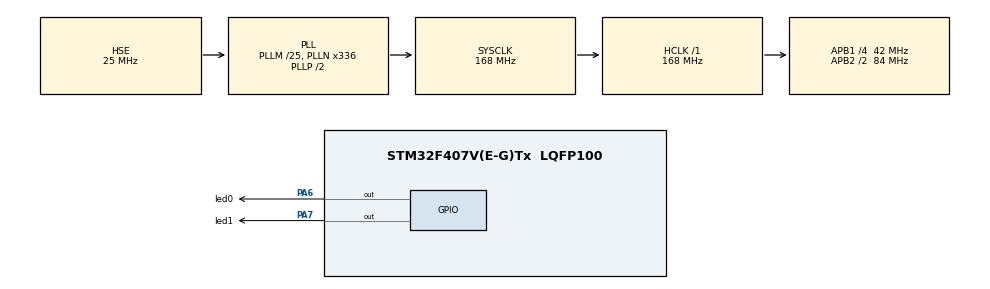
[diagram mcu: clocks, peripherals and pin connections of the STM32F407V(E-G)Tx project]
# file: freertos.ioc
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FREERTOS.Tasks01=task_led0,24,128,task_led0_start,Default,NULL,Dynamic,NULL,NULL;task_led1,24,128,task_led1_start,Default,NULL,Dynamic,NULL,NULL
Mcu.Family=STM32F4
Mcu.Name=STM32F407V(E-G)Tx
Mcu.Package=LQFP100
NVIC.PriorityGroup=NVIC_PRIORITYGROUP_4
PA13.Mode=Serial_Wire
PA13.Signal=SYS_JTMS-SWDIO
PA14.Mode=Serial_Wire
PA14.Signal=SYS_JTCK-SWCLK
PA6.GPIO_Label=led0
PA6.Signal=GPIO_Output
PA7.GPIO_Label=led1
PA7.Signal=GPIO_Output
PC14-OSC32_IN.Mode=LSE-External-Oscillator
PC14-OSC32_IN.Signal=RCC_OSC32_IN
PC15-OSC32_OUT.Mode=LSE-External-Oscillator
PC15-OSC32_OUT.Signal=RCC_OSC32_OUT
PH0-OSC_IN.Mode=HSE-External-Oscillator
PH0-OSC_IN.Signal=RCC_OSC_IN
PH1-OSC_OUT.Mode=HSE-External-Oscillator
PH1-OSC_OUT.Signal=RCC_OSC_OUT
ProjectManager.HeapSize=0x200
ProjectManager.StackSize=0x400
ProjectManager.TargetToolchain=STM32CubeIDE
RCC.48MHZClocksFreq_Value=84000000
RCC.AHBFreq_Value=168000000
RCC.APB1CLKDivider=RCC_HCLK_DIV4
RCC.APB1Freq_Value=42000000
RCC.APB1TimFreq_Value=84000000
RCC.APB2CLKDivider=RCC_HCLK_DIV2
RCC.APB2Freq_Value=84000000
RCC.APB2TimFreq_Value=168000000
RCC.CortexFreq_Value=168000000
RCC.HCLKFreq_Value=168000000
RCC.HSE_VALUE=25000000
RCC.HSI_VALUE=16000000
RCC.PLLM=25
RCC.PLLN=336
RCC.PLLSourceVirtual=RCC_PLLSOURCE_HSE
RCC.SYSCLKFreq_VALUE=168000000
RCC.SYSCLKSource=RCC_SYSCLKSOURCE_PLLCLK
RCC.VCOOutputFreq_Value=336000000
VP_FREERTOS_VS_CMSIS_V2.Mode=CMSIS_V2
board=custom

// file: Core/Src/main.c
/* USER CODE BEGIN Header */
/**
  ******************************************************************************
  * @file           : main.c
  * @brief          : Main program body
  ******************************************************************************
  * @attention
  *
  * <h2><center>&copy; Copyright (c) 2021 STMicroelectronics.
  * All rights reserved.</center></h2>
  *
  * This software component is licensed by ST under BSD 3-Clause license,
  * the "License"; You may not use this file except in compliance with the
  * License. You may obtain a copy of the License at:
  *                        opensource.org/licenses/BSD-3-Clause
  *
  ******************************************************************************
  */
/* USER CODE END Header */
#include "main.h"
#include "cmsis_os.h"
#include "gpio.h"

void SystemClock_Config(void);
void MX_FREERTOS_Init(void);

int main(void)
{

  /* MCU Configuration--------------------------------------------------------*/

  /* Reset of all peripherals, Initializes the Flash interface and the Systick. */
  HAL_Init();

  /* Configure the system clock */
  SystemClock_Config();

  /* Initialize all configured peripherals */
  MX_GPIO_Init();

  /* Init scheduler */
  osKernelInitialize();  /* Call init function for freertos objects (in freertos.c) */
  MX_FREERTOS_Init();
  /* Start scheduler */
  osKernelStart();

  /* We should never get here as control is now taken by the scheduler */
  /* Infinite loop */
  while (1)
  {

  }
}

void SystemClock_Config(void)
{
  RCC_OscInitTypeDef RCC_OscInitStruct = {0};
  RCC_ClkInitTypeDef RCC_ClkInitStruct = {0};

  /** Configure the main internal regulator output voltage
  */
  __HAL_RCC_PWR_CLK_ENABLE();
  __HAL_PWR_VOLTAGESCALING_CONFIG(PWR_REGULATOR_VOLTAGE_SCALE1);
  /** Initializes the RCC Oscillators according to the specified parameters
  * in the RCC_OscInitTypeDef structure.
  */
  RCC_OscInitStruct.OscillatorType = RCC_OSCILLATORTYPE_HSE;
  RCC_OscInitStruct.HSEState = RCC_HSE_ON;
  RCC_OscInitStruct.PLL.PLLState = RCC_PLL_ON;
  RCC_OscInitStruct.PLL.PLLSource = RCC_PLLSOURCE_HSE;
  RCC_OscInitStruct.PLL.PLLM = 25;
  RCC_OscInitStruct.PLL.PLLN = 336;
  RCC_OscInitStruct.PLL.PLLP = RCC_PLLP_DIV2;
  RCC_OscInitStruct.PLL.PLLQ = 4;
  if (HAL_RCC_OscConfig(&RCC_OscInitStruct) != HAL_OK)
  {
    Error_Handler();
  }
  /** Initializes the CPU, AHB and APB buses clocks
  */
  RCC_ClkInitStruct.ClockType = RCC_CLOCKTYPE_HCLK|RCC_CLOCKTYPE_SYSCLK
                              |RCC_CLOCKTYPE_PCLK1|RCC_CLOCKTYPE_PCLK2;
  RCC_ClkInitStruct.SYSCLKSource = RCC_SYSCLKSOURCE_PLLCLK;
  RCC_ClkInitStruct.AHBCLKDivider = RCC_SYSCLK_DIV1;
  RCC_ClkInitStruct.APB1CLKDivider = RCC_HCLK_DIV4;
  RCC_ClkInitStruct.APB2CLKDivider = RCC_HCLK_DIV2;

  if (HAL_RCC_ClockConfig(&RCC_ClkInitStruct, FLASH_LATENCY_5) != HAL_OK)
  {
    Error_Handler();
  }
}

void Error_Handler(void)
{
  __disable_irq();
  while (1)
  {
  }
}

/************************ (C) COPYRIGHT STMicroelectronics *****END OF FILE****/

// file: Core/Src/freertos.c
/* USER CODE BEGIN Header */
/**
 ******************************************************************************
 * File Name          : freertos.c
 * Description        : Code for freertos applications
 ******************************************************************************
 * @attention
 *
 * <h2><center>&copy; Copyright (c) 2021 STMicroelectronics.
 * All rights reserved.</center></h2>
 *
 * This software component is licensed by ST under Ultimate Liberty license
 * SLA0044, the "License"; You may not use this file except in compliance with
 * the License. You may obtain a copy of the License at:
 *                             www.st.com/SLA0044
 *
 ******************************************************************************
 */
/* USER CODE END Header */

#include "FreeRTOS.h"
#include "task.h"
#include "main.h"
#include "cmsis_os.h"

/* Definitions for task_led0 */
osThreadId_t task_led0Handle;
const osThreadAttr_t task_led0_attributes = { .name = "task_led0", .stack_size =
		128 * 4, .priority = (osPriority_t) osPriorityNormal, };
/* Definitions for task_led1 */
osThreadId_t task_led1Handle;
const osThreadAttr_t task_led1_attributes = { .name = "task_led1", .stack_size =
		128 * 4, .priority = (osPriority_t) osPriorityNormal, };

void task_led0_start(void *argument);
void task_led1_start(void *argument);

void MX_FREERTOS_Init(void); /* (MISRA C 2004 rule 8.1) */

void MX_FREERTOS_Init(void) {

	/* Create the thread(s) */
	/* creation of task_led0 */
	task_led0Handle = osThreadNew(task_led0_start, NULL, &task_led0_attributes);

	/* creation of task_led1 */
	task_led1Handle = osThreadNew(task_led1_start, NULL, &task_led1_attributes);

}

void task_led0_start(void *argument) {
	/* USER CODE BEGIN task_led0_start */
	HAL_GPIO_WritePin(GPIOA, led0_Pin, GPIO_PIN_RESET);
	/* Infinite loop */
	for (;;) {
		HAL_GPIO_TogglePin(GPIOA, led0_Pin);
		osDelay(80);
	}
	/* USER CODE END task_led0_start */
}

void task_led1_start(void *argument) {
	/* USER CODE BEGIN task_led1_start */
	HAL_GPIO_WritePin(GPIOA, led1_Pin, GPIO_PIN_RESET);
	/* Infinite loop */
	for (;;) {
		HAL_GPIO_TogglePin(GPIOA, led1_Pin);
		osDelay(200);
	}
	/* USER CODE END task_led1_start */
}

/************************ (C) COPYRIGHT STMicroelectronics *****END OF FILE****/
